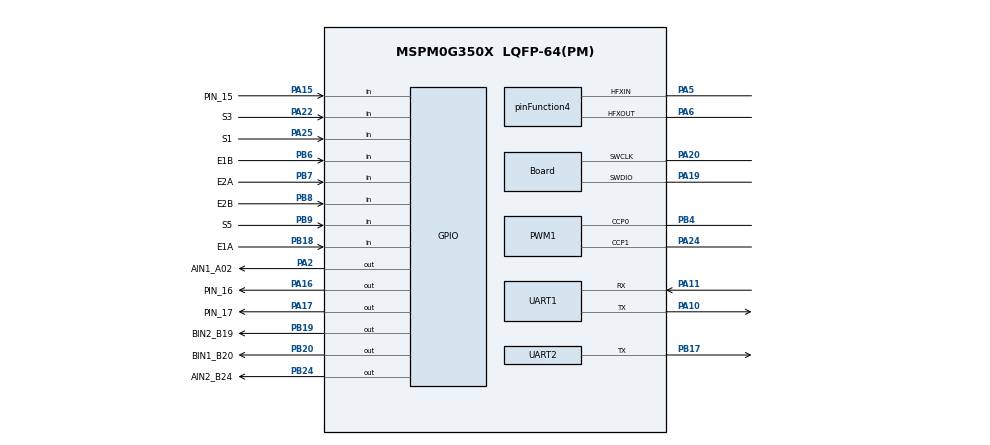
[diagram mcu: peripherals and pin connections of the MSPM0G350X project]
/**
 * @cliArgs --device "MSPM0G350X" --package "LQFP-64(PM)" --part "Default" --product "mspm0_sdk@2.01.00.03"
 * @versions {"tool":"1.20.0+3587"}
 */

/**
 * Import the modules used in this configuration.
 */
const GPIO          = scripting.addModule("/ti/driverlib/GPIO", {}, false);
const GPIO1         = GPIO.addInstance();
const GPIO2         = GPIO.addInstance();
const GPIO3         = GPIO.addInstance();
const GPIO4         = GPIO.addInstance();
const GPIO5         = GPIO.addInstance();
const GPIO6         = GPIO.addInstance();
const GPIO7         = GPIO.addInstance();
const GPIO8         = GPIO.addInstance();
const I2C           = scripting.addModule("/ti/driverlib/I2C", {}, false);
const I2C1          = I2C.addInstance();
const PWM           = scripting.addModule("/ti/driverlib/PWM", {}, false);
const PWM1          = PWM.addInstance();
const SYSCTL        = scripting.addModule("/ti/driverlib/SYSCTL");
const SYSTICK       = scripting.addModule("/ti/driverlib/SYSTICK");
const TIMER         = scripting.addModule("/ti/driverlib/TIMER", {}, false);
const TIMER1        = TIMER.addInstance();
const UART          = scripting.addModule("/ti/driverlib/UART", {}, false);
const UART1         = UART.addInstance();
const UART2         = UART.addInstance();
const ProjectConfig = scripting.addModule("/ti/project_config/ProjectConfig");

/**
 * Write custom configuration values to the imported modules.
 */
const divider9       = system.clockTree["UDIV"];
divider9.divideValue = 2;

const gate7  = system.clockTree["MFCLKGATE"];
gate7.enable = true;

const multiplier2         = system.clockTree["PLL_QDIV"];
multiplier2.multiplyValue = 4;

const mux3       = system.clockTree["EXCLKMUX"];
mux3.inputSelect = "EXCLKMUX_PLLCLK1_OUT";

const mux4       = system.clockTree["EXHFMUX"];
mux4.inputSelect = "EXHFMUX_XTAL";

const mux8       = system.clockTree["HSCLKMUX"];
mux8.inputSelect = "HSCLKMUX_SYSPLL0";

const mux12       = system.clockTree["SYSPLLMUX"];
mux12.inputSelect = "zSYSPLLMUX_HFCLK";

const pinFunction4                        = system.clockTree["HFXT"];
pinFunction4.inputFreq                    = 40;
pinFunction4.enable                       = true;
pinFunction4.HFXTStartup                  = 10;
pinFunction4.peripheral.$assign           = "SYSCTL";
pinFunction4.peripheral.hfxInPin.$assign  = "PA5";
pinFunction4.peripheral.hfxOutPin.$assign = "PA6";

GPIO1.$name                              = "LED1";
GPIO1.port                               = "PORTA";
GPIO1.associatedPins[0].$name            = "PIN_14";
GPIO1.associatedPins[0].internalResistor = "PULL_DOWN";
GPIO1.associatedPins[0].assignedPin      = "14";

const Board                       = scripting.addModule("/ti/driverlib/Board", {}, false);
Board.peripheral.$assign          = "DEBUGSS";
Board.peripheral.swclkPin.$assign = "PA20";
Board.peripheral.swdioPin.$assign = "PA19";

GPIO2.$name                              = "KEY";
GPIO2.port                               = "PORTA";
GPIO2.associatedPins.create(4);
GPIO2.associatedPins[0].direction        = "INPUT";
GPIO2.associatedPins[0].internalResistor = "PULL_DOWN";
GPIO2.associatedPins[0].interruptEn      = true;
GPIO2.associatedPins[0].polarity         = "RISE";
GPIO2.associatedPins[0].$name            = "PIN_15";
GPIO2.associatedPins[0].assignedPin      = "15";
GPIO2.associatedPins[0].pin.$assign      = "PA15";
GPIO2.associatedPins[1].$name            = "PIN_16";
GPIO2.associatedPins[1].assignedPin      = "16";
GPIO2.associatedPins[1].pin.$assign      = "PA16";
GPIO2.associatedPins[2].$name            = "PIN_17";
GPIO2.associatedPins[2].assignedPin      = "17";
GPIO2.associatedPins[2].pin.$assign      = "PA17";
GPIO2.associatedPins[3].assignedPin      = "21";
GPIO2.associatedPins[3].$name            = "PIN_21";

GPIO3.$name                               = "ENCODER";
GPIO3.associatedPins.create(4);
GPIO3.associatedPins[0].$name             = "E1A";
GPIO3.associatedPins[0].direction         = "INPUT";
GPIO3.associatedPins[0].assignedPort      = "PORTB";
GPIO3.associatedPins[0].assignedPin       = "18";
GPIO3.associatedPins[0].interruptEn       = true;
GPIO3.associatedPins[0].interruptPriority = "0";
GPIO3.associatedPins[0].polarity          = "RISE";
GPIO3.associatedPins[0].pin.$assign       = "PB18";
GPIO3.associatedPins[1].$name             = "E1B";
GPIO3.associatedPins[1].direction         = "INPUT";
GPIO3.associatedPins[1].assignedPort      = "PORTB";
GPIO3.associatedPins[1].assignedPin       = "6";
GPIO3.associatedPins[1].interruptEn       = true;
GPIO3.associatedPins[1].interruptPriority = "0";
GPIO3.associatedPins[1].polarity          = "RISE";
GPIO3.associatedPins[1].pin.$assign       = "PB6";
GPIO3.associatedPins[2].$name             = "E2A";
GPIO3.associatedPins[2].direction         = "INPUT";
GPIO3.associatedPins[2].assignedPort      = "PORTB";
GPIO3.associatedPins[2].assignedPin       = "7";
GPIO3.associatedPins[2].interruptEn       = true;
GPIO3.associatedPins[2].interruptPriority = "0";
GPIO3.associatedPins[2].polarity          = "RISE";
GPIO3.associatedPins[2].pin.$assign       = "PB7";
GPIO3.associatedPins[3].$name             = "E2B";
GPIO3.associatedPins[3].direction         = "INPUT";
GPIO3.associatedPins[3].assignedPort      = "PORTB";
GPIO3.associatedPins[3].assignedPin       = "8";
GPIO3.associatedPins[3].interruptEn       = true;
GPIO3.associatedPins[3].interruptPriority = "0";
GPIO3.associatedPins[3].polarity          = "RISE";
GPIO3.associatedPins[3].pin.$assign       = "PB8";

GPIO4.$name                          = "MOTOR";
GPIO4.associatedPins.create(4);
GPIO4.associatedPins[0].$name        = "AIN1_A02";
GPIO4.associatedPins[0].assignedPort = "PORTA";
GPIO4.associatedPins[0].assignedPin  = "2";
GPIO4.associatedPins[0].pin.$assign  = "PA2";
GPIO4.associatedPins[1].$name        = "AIN2_B24";
GPIO4.associatedPins[1].assignedPort = "PORTB";
GPIO4.associatedPins[1].assignedPin  = "24";
GPIO4.associatedPins[1].pin.$assign  = "PB24";
GPIO4.associatedPins[2].$name        = "BIN1_B20";
GPIO4.associatedPins[2].assignedPort = "PORTB";
GPIO4.associatedPins[2].assignedPin  = "20";
GPIO4.associatedPins[2].pin.$assign  = "PB20";
GPIO4.associatedPins[3].$name        = "BIN2_B19";
GPIO4.associatedPins[3].assignedPort = "PORTB";
GPIO4.associatedPins[3].assignedPin  = "19";
GPIO4.associatedPins[3].pin.$assign  = "PB19";

GPIO5.$name                          = "GYRO";
GPIO5.port                           = "PORTA";
GPIO5.associatedPins.create(2);
GPIO5.associatedPins[0].$name        = "SCL";
GPIO5.associatedPins[0].initialValue = "SET";
GPIO5.associatedPins[0].assignedPin  = "1";
GPIO5.associatedPins[0].ioStructure  = "OD";
GPIO5.associatedPins[1].$name        = "SDA";
GPIO5.associatedPins[1].initialValue = "SET";
GPIO5.associatedPins[1].ioStructure  = "OD";
GPIO5.associatedPins[1].assignedPin  = "0";

GPIO6.$name                          = "TRACK";
GPIO6.associatedPins.create(5);
GPIO6.associatedPins[0].$name        = "S1";
GPIO6.associatedPins[0].direction    = "INPUT";
GPIO6.associatedPins[0].assignedPort = "PORTA";
GPIO6.associatedPins[0].assignedPin  = "25";
GPIO6.associatedPins[0].pin.$assign  = "PA25";
GPIO6.associatedPins[1].$name        = "S2";
GPIO6.associatedPins[1].direction    = "INPUT";
GPIO6.associatedPins[1].assignedPort = "PORTA";
GPIO6.associatedPins[1].assignedPin  = "12";
GPIO6.associatedPins[2].$name        = "S3";
GPIO6.associatedPins[2].direction    = "INPUT";
GPIO6.associatedPins[2].assignedPort = "PORTA";
GPIO6.associatedPins[2].assignedPin  = "22";
GPIO6.associatedPins[2].pin.$assign  = "PA22";
GPIO6.associatedPins[3].$name        = "S4";
GPIO6.associatedPins[3].direction    = "INPUT";
GPIO6.associatedPins[3].assignedPort = "PORTA";
GPIO6.associatedPins[3].assignedPin  = "13";
GPIO6.associatedPins[4].$name        = "S5";
GPIO6.associatedPins[4].direction    = "INPUT";
GPIO6.associatedPins[4].assignedPort = "PORTB";
GPIO6.associatedPins[4].assignedPin  = "9";
GPIO6.associatedPins[4].pin.$assign  = "PB9";

GPIO7.$name                         = "OLED";
GPIO7.port                          = "PORTB";
GPIO7.associatedPins.create(3);
GPIO7.associatedPins[0].$name       = "RES";
GPIO7.associatedPins[0].assignedPin = "10";
GPIO7.associatedPins[1].$name       = "DC";
GPIO7.associatedPins[1].assignedPin = "1";
GPIO7.associatedPins[2].$name       = "CS";
GPIO7.associatedPins[2].assignedPin = "0";

GPIO8.$name                              = "BEEP";
GPIO8.port                               = "PORTB";
GPIO8.associatedPins[0].$name            = "PIN_12";
GPIO8.associatedPins[0].internalResistor = "PULL_DOWN";
GPIO8.associatedPins[0].assignedPin      = "12";

I2C1.basicEnableController             = true;
I2C1.basicClockSourceDivider           = 4;
I2C1.basicControllerBusSpeed           = 500000;
I2C1.$name                             = "I2C_OLED";
I2C1.sdaPinConfig.hideOutputInversion  = scripting.forceWrite(false);
I2C1.sdaPinConfig.onlyInternalResistor = scripting.forceWrite(false);
I2C1.sdaPinConfig.passedPeripheralType = scripting.forceWrite("Digital");
I2C1.sdaPinConfig.$name                = "ti_driverlib_gpio_GPIOPinGeneric4";
I2C1.sclPinConfig.hideOutputInversion  = scripting.forceWrite(false);
I2C1.sclPinConfig.onlyInternalResistor = scripting.forceWrite(false);
I2C1.sclPinConfig.passedPeripheralType = scripting.forceWrite("Digital");
I2C1.sclPinConfig.$name                = "ti_driverlib_gpio_GPIOPinGeneric5";

PWM1.$name                              = "PWM_MOTOR";
PWM1.timerCount                         = 10000;
PWM1.timerStartTimer                    = true;
PWM1.peripheral.ccp0Pin.$assign         = "PB4";
PWM1.peripheral.ccp1Pin.$assign         = "PA24";
PWM1.PWM_CHANNEL_0.$name                = "ti_driverlib_pwm_PWMTimerCC0";
PWM1.PWM_CHANNEL_0.invert               = true;
PWM1.PWM_CHANNEL_1.$name                = "ti_driverlib_pwm_PWMTimerCC1";
PWM1.PWM_CHANNEL_1.invert               = true;
PWM1.ccp0PinConfig.$name                = "ti_driverlib_gpio_GPIOPinGeneric2";
PWM1.ccp0PinConfig.direction            = scripting.forceWrite("OUTPUT");
PWM1.ccp0PinConfig.hideOutputInversion  = scripting.forceWrite(false);
PWM1.ccp0PinConfig.onlyInternalResistor = scripting.forceWrite(false);
PWM1.ccp0PinConfig.passedPeripheralType = scripting.forceWrite("Digital");
PWM1.ccp1PinConfig.$name                = "ti_driverlib_gpio_GPIOPinGeneric3";
PWM1.ccp1PinConfig.direction            = scripting.forceWrite("OUTPUT");
PWM1.ccp1PinConfig.hideOutputInversion  = scripting.forceWrite(false);
PWM1.ccp1PinConfig.onlyInternalResistor = scripting.forceWrite(false);
PWM1.ccp1PinConfig.passedPeripheralType = scripting.forceWrite("Digital");

SYSCTL.forceDefaultClkConfig = true;
SYSCTL.clockTreeEn           = true;
SYSCTL.useHFCLK_Manual       = true;

SYSTICK.periodEnable      = true;
SYSTICK.systickEnable     = true;
SYSTICK.interruptPriority = "0";
SYSTICK.period            = 80;

TIMER1.$name              = "TIMER_0";
TIMER1.timerClkSrc        = "MFCLK";
TIMER1.timerClkPrescale   = 200;
TIMER1.timerPeriod        = "5ms";
TIMER1.timerStartTimer    = true;
TIMER1.interrupts         = ["ZERO"];
TIMER1.interruptPriority  = "3";
TIMER1.timerMode          = "PERIODIC";
TIMER1.peripheral.$assign = "TIMA0";

UART1.uartClkSrc                       = "MFCLK";
UART1.$name                            = "UART_0_DEBUG";
UART1.interruptPriority                = "3";
UART1.targetBaudRate                   = 115200;
UART1.peripheral.$assign               = "UART0";
UART1.peripheral.rxPin.$assign         = "PA11";
UART1.peripheral.txPin.$assign         = "PA10";
UART1.txPinConfig.direction            = scripting.forceWrite("OUTPUT");
UART1.txPinConfig.hideOutputInversion  = scripting.forceWrite(false);
UART1.txPinConfig.onlyInternalResistor = scripting.forceWrite(false);
UART1.txPinConfig.passedPeripheralType = scripting.forceWrite("Digital");
UART1.txPinConfig.$name                = "ti_driverlib_gpio_GPIOPinGeneric0";
UART1.rxPinConfig.hideOutputInversion  = scripting.forceWrite(false);
UART1.rxPinConfig.onlyInternalResistor = scripting.forceWrite(false);
UART1.rxPinConfig.passedPeripheralType = scripting.forceWrite("Digital");
UART1.rxPinConfig.$name                = "ti_driverlib_gpio_GPIOPinGeneric1";

UART2.$name                            = "UART_JY61P";
UART2.uartClkSrc                       = "MFCLK";
UART2.enabledInterrupts                = ["RX"];
UART2.peripheral.$assign               = "UART2";
UART2.peripheral.txPin.$assign         = "PB17";
UART2.txPinConfig.$name                = "ti_driverlib_gpio_GPIOPinGeneric6";
UART2.txPinConfig.direction            = scripting.forceWrite("OUTPUT");
UART2.txPinConfig.hideOutputInversion  = scripting.forceWrite(false);
UART2.txPinConfig.onlyInternalResistor = scripting.forceWrite(false);
UART2.txPinConfig.passedPeripheralType = scripting.forceWrite("Digital");
UART2.rxPinConfig.$name                = "ti_driverlib_gpio_GPIOPinGeneric7";
UART2.rxPinConfig.hideOutputInversion  = scripting.forceWrite(false);
UART2.rxPinConfig.onlyInternalResistor = scripting.forceWrite(false);
UART2.rxPinConfig.passedPeripheralType = scripting.forceWrite("Digital");

ProjectConfig.deviceSpin = "MSPM0G3507";
scripting.suppress("Migrating requires going through the Switch Board or Device menu in the Device View section\\.", ProjectConfig, "deviceSpin");

/**
 * Pinmux solution for unlocked pins/peripherals. This ensures that minor changes to the automatic solver in a future
 * version of the tool will not impact the pinmux you originally saw.  These lines can be completely deleted in order to
 * re-solve from scratch.
 */
GPIO1.associatedPins[0].pin.$suggestSolution = "PA14";
GPIO2.associatedPins[3].pin.$suggestSolution = "PA21";
GPIO5.associatedPins[0].pin.$suggestSolution = "PA1";
GPIO5.associatedPins[1].pin.$suggestSolution = "PA0";
GPIO6.associatedPins[1].pin.$suggestSolution = "PA12";
GPIO6.associatedPins[3].pin.$suggestSolution = "PA13";
GPIO7.associatedPins[0].pin.$suggestSolution = "PB10";
GPIO7.associatedPins[1].pin.$suggestSolution = "PB1";
GPIO7.associatedPins[2].pin.$suggestSolution = "PB0";
GPIO8.associatedPins[0].pin.$suggestSolution = "PB12";
I2C1.peripheral.$suggestSolution             = "I2C0";
I2C1.peripheral.sdaPin.$suggestSolution      = "PA28";
I2C1.peripheral.sclPin.$suggestSolution      = "PA31";
PWM1.peripheral.$suggestSolution             = "TIMA1";
UART2.peripheral.rxPin.$suggestSolution      = "PB16";
